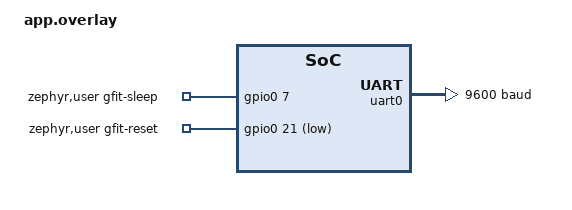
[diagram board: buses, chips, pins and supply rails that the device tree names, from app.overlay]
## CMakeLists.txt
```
# SPDX-License-Identifier: Apache-2.0

cmake_minimum_required(VERSION 3.20.0)
find_package(Zephyr REQUIRED HINTS $ENV{ZEPHYR_BASE})
project(d52q_gfit_bridge)

target_sources(app PRIVATE
	src/main.c
	src/ble_ftms.c
	src/gfit_protocol.c
)
```

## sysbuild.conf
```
# Build MCUboot together with the application for the initial programmer flash.
SB_CONFIG_BOOTLOADER_MCUBOOT=y
```

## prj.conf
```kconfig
CONFIG_GPIO=y
CONFIG_SERIAL=y
CONFIG_UART_INTERRUPT_DRIVEN=y
CONFIG_CONSOLE=n
CONFIG_UART_CONSOLE=n

CONFIG_BT=y
CONFIG_BT_PERIPHERAL=y
CONFIG_BT_DEVICE_NAME="N-Bike"
CONFIG_BT_DEVICE_NAME_DYNAMIC=y
CONFIG_BT_DEVICE_APPEARANCE=1152

# OTA path for nRF Connect / Device Manager. Final partition sizing must be
# verified on the exact D52Q board and flash layout.
CONFIG_BOOTLOADER_MCUBOOT=y
CONFIG_MCUBOOT_SIGNATURE_KEY_FILE="C:/ncs/v3.3.1/bootloader/mcuboot/root-rsa-2048.pem"
CONFIG_FLASH=y
CONFIG_FLASH_MAP=y
CONFIG_STREAM_FLASH=y
CONFIG_ZCBOR=y
CONFIG_CRC=y
CONFIG_IMG_MANAGER=y
CONFIG_MCUMGR=y
CONFIG_MCUMGR_GRP_IMG=y
CONFIG_MCUMGR_GRP_OS=y
CONFIG_MCUMGR_TRANSPORT_BT=y
CONFIG_BT_L2CAP_TX_MTU=252
CONFIG_BT_BUF_ACL_RX_SIZE=256
CONFIG_BT_BUF_ACL_TX_SIZE=256
CONFIG_SYSTEM_WORKQUEUE_STACK_SIZE=2304
CONFIG_MAIN_STACK_SIZE=2176
```

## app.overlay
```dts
&pinctrl {
	uart0_default: uart0_default {
		group1 {
			psels = <NRF_PSEL(UART_TX, 0, 17)>,
				<NRF_PSEL(UART_RX, 0, 16)>;
		};
	};

	uart0_sleep: uart0_sleep {
		group1 {
			psels = <NRF_PSEL(UART_RX, 0, 16)>;
			low-power-enable;
		};

		group2 {
			psels = <NRF_PSEL(UART_TX, 0, 17)>;
			low-power-enable;
			bias-pull-up;
		};
	};
};

&uart0 {
	status = "okay";
	current-speed = <9600>;
	/delete-property/ hw-flow-control;
};

/ {
	zephyr,user {
		gfit-sleep-gpios = <&gpio0 7 GPIO_ACTIVE_HIGH>;
		gfit-reset-gpios = <&gpio0 21 GPIO_ACTIVE_LOW>;
	};
};
```

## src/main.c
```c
#include <stddef.h>
#include <stdint.h>
#include <string.h>
#include <zephyr/drivers/gpio.h>
#include <zephyr/drivers/uart.h>
#include <zephyr/kernel.h>

#include "ble_ftms.h"
#include "gfit_protocol.h"

#define UART_DEVICE_NODE DT_NODELABEL(uart0)
#define USER_NODE DT_PATH(zephyr_user)
#define UART_RX_RING_SIZE 256
#define GFIT_POLL_MS 5

#define GFIT_BOOT 0x6f
#define GFIT_EVENT 0xe0
#define GFIT_CUSTOM_EVENT 0xb1
#define GFIT_HR_EVENT 0xb2
#define GFIT_CONTROL_EVENT 0xb5
#define GFIT_PERIPHERAL_EVENT 0xba
#define GFIT_METRIC_PACKET 0xe1
#define GFIT_COMMAND 0xe2
#define GFIT_CUSTOM_PROTOCOL 0xfe

#define GFIT_CMD_SET_EQUIPMENT 0xe0
#define GFIT_CMD_SET_METRICS 0xe1
#define GFIT_CMD_SET_CHANNEL_CONFIGURATION 0xd1
#define GFIT_CMD_TRANSITION 0xd0
#define GFIT_CMD_SET_DEVICE_INFO 0xe4
#define GFIT_CMD_SET_HRP_PAIRING 0xe5
#define GFIT_CMD_GET_VERSION 0xd7
#define GFIT_CMD_HRP_DISCONNECT 0xd9

#define GFIT_DEVICE_INFO_HARDWARE 0x02
#define GFIT_DEVICE_INFO_FIRMWARE 0x04
#define GFIT_DEVICE_INFO_PRODUCT 0x05
#define GFIT_DEVICE_INFO_MANUFACTURER 0x06

#define GFIT_TAG_SPEED 0x21
#define GFIT_TAG_CADENCE 0x22
#define GFIT_TAG_POWER 0x2a
#define GFIT_TAG_RESISTANCE 0x33

#define GFIT_TRANSITION_READY 0x04

struct ring_buffer {
	uint16_t start;
	uint16_t end;
	uint8_t data[UART_RX_RING_SIZE];
};

struct bike_metrics {
	uint16_t speed_centi_kmh;
	uint16_t cadence_half_rpm;
	int16_t resistance_percent;
	int16_t power_watt;
};

struct gfit_config {
	uint8_t equipment_type;
	uint8_t equipment_flags[2];
	uint8_t channel_selector;
	uint8_t channel_mask;
	uint8_t state;
	uint8_t metric_template[GFIT_PAYLOAD_MAX];
	uint8_t metric_template_length;
	char product_name[21];
	char manufacturer_name[21];
	char firmware_revision[8];
	char hardware_revision[8];
};

static const struct device *const uart_dev = DEVICE_DT_GET(UART_DEVICE_NODE);
static const struct gpio_dt_spec gfit_sleep =
	GPIO_DT_SPEC_GET(USER_NODE, gfit_sleep_gpios);
static const struct gpio_dt_spec gfit_reset =
	GPIO_DT_SPEC_GET(USER_NODE, gfit_reset_gpios);
static struct ring_buffer uart_rx;
static struct gfit_parser parser;
static struct bike_metrics last_metrics;
static struct gfit_config gfit_config = {
	.product_name = "N-Bike",
	.manufacturer_name = "Waterrower GmbH",
};
static bool bridge_ready;
static bool gfit_control_active;

static bool ring_is_empty(const struct ring_buffer *ring)
{
	return ring->start == ring->end;
}

static bool ring_is_full(const struct ring_buffer *ring)
{
	return ((ring->end + 1U) % UART_RX_RING_SIZE) == ring->start;
}

static void ring_write(struct ring_buffer *ring, uint8_t byte)
{
	if (ring_is_full(ring)) {
		ring->start = (ring->start + 1U) % UART_RX_RING_SIZE;
	}
	ring->data[ring->end] = byte;
	ring->end = (ring->end + 1U) % UART_RX_RING_SIZE;
}

static uint8_t ring_read(struct ring_buffer *ring)
{
	uint8_t byte = 0;

	if (!ring_is_empty(ring)) {
		byte = ring->data[ring->start];
		ring->start = (ring->start + 1U) % UART_RX_RING_SIZE;
	}

	return byte;
}

static void uart_send(const uint8_t *data, size_t length)
{
	for (size_t i = 0; i < length; i++) {
		uart_poll_out(uart_dev, data[i]);
	}
}

static void gfit_send_payload(const uint8_t *payload, size_t length)
{
	uint8_t frame[GFIT_PAYLOAD_MAX + 3U];
	size_t frame_length;

	if (length > GFIT_PAYLOAD_MAX) {
		return;
	}

	gfit_make_frame(payload, length, frame, &frame_length);
	uart_send(frame, frame_length);
}

static void gfit_send_boot_event(void)
{
	const uint8_t payload[] = { GFIT_BOOT };

	gfit_send_payload(payload, sizeof(payload));
}

static void gfit_send_response(bool success)
{
	const uint8_t payload[] = {
		GFIT_COMMAND, 0xb0, GFIT_CUSTOM_PROTOCOL,
		0x01, success ? 0x01 : 0x00, 0x01, 0x00, 0x00,
	};

	gfit_send_payload(payload, sizeof(payload));
}

static void gfit_send_calibrated_status(bool calibrated)
{
	const uint8_t payload[] = {
		0x02, 0x01, calibrated ? 0x01 : 0x02, 0x00, 0x00,
	};

	gfit_send_payload(payload, sizeof(payload));
}

static void gfit_send_peripheral_event(bool connected)
{
	const uint8_t payload[] = {
		GFIT_EVENT, GFIT_PERIPHERAL_EVENT, connected ? 0x00 : 0x01,
	};

	gfit_send_payload(payload, sizeof(payload));
}

static void copy_ascii_field(char *target, size_t target_size,
			     const uint8_t *source, size_t source_length)
{
	size_t length = MIN(source_length, target_size - 1U);

	memcpy(target, source, length);
	target[length] = '\0';
}

static void copy_hex_revision(char *target, size_t target_size,
			      const uint8_t *source, size_t source_length)
{
	size_t pos = 0;

	for (size_t i = 0; i < source_length && pos + 2U < target_size; i++) {
		static const char hex[] = "0123456789ABCDEF";

		target[pos++] = hex[(source[i] >> 4) & 0x0f];
		target[pos++] = hex[source[i] & 0x0f];
	}
	target[pos] = '\0';
}

static uint16_t get_le16(const uint8_t *data)
{
	return (uint16_t)data[0] | ((uint16_t)data[1] << 8);
}

static void handle_metric_packet(const uint8_t *payload, size_t length)
{
	size_t pos = 2;

	while (pos < length) {
		uint8_t tag = payload[pos++];

		switch (tag) {
		case GFIT_TAG_CADENCE:
			if (pos + 2U <= length) {
				last_metrics.cadence_half_rpm = get_le16(&payload[pos]);
				pos += 2U;
			}
			break;
		case GFIT_TAG_RESISTANCE:
			if (pos + 2U <= length) {
				uint16_t raw = get_le16(&payload[pos]);

				last_metrics.resistance_percent = (int16_t)(raw / 2U);
				pos += 2U;
			}
			break;
		case GFIT_TAG_POWER:
			if (pos + 2U <= length) {
				last_metrics.power_watt = (int16_t)get_le16(&payload[pos]);
				pos += 2U;
			}
			break;
		case GFIT_TAG_SPEED:
			if (pos + 2U <= length) {
				uint16_t mm_per_sec = get_le16(&payload[pos]);
				uint32_t centi_kmh = ((uint32_t)mm_per_sec * 36U) / 100U;

				last_metrics.speed_centi_kmh = (uint16_t)centi_kmh;
				pos += 2U;
			}
			break;
		default:
			pos = length;
			break;
		}
	}

	(void)ble_ftms_notify_indoor_bike(last_metrics.speed_centi_kmh,
					  last_metrics.cadence_half_rpm,
					  last_metrics.resistance_percent,
					  last_metrics.power_watt);
}

static void handle_custom_protocol(const uint8_t *payload, size_t length)
{
	uint8_t operation;
	uint8_t target;

	if (length < 5U) {
		gfit_send_response(false);
		return;
	}

	operation = payload[3];
	target = payload[4];

	if (operation == 0x02U && (target == 0x01U || target == 0x02U)) {
		gfit_send_response(true);
		return;
	}

	if (operation == 0x04U) {
		gfit_send_response(true);
		gfit_send_calibrated_status(true);
		return;
	}

	gfit_send_response(false);
}

static void handle_device_info_command(const uint8_t *payload, size_t length)
{
	uint8_t info_type;
	const uint8_t *data;
	size_t data_length;

	if (length < 4U) {
		gfit_send_response(false);
		return;
	}

	info_type = payload[2];
	data = &payload[3];
	data_length = length - 3U;

	switch (info_type) {
	case GFIT_DEVICE_INFO_PRODUCT:
		copy_ascii_field(gfit_config.product_name,
				 sizeof(gfit_config.product_name),
				 data, data_length);
		(void)ble_ftms_set_name(gfit_config.product_name);
		break;
	case GFIT_DEVICE_INFO_MANUFACTURER:
		copy_ascii_field(gfit_config.manufacturer_name,
				 sizeof(gfit_config.manufacturer_name),
				 data, data_length);
		break;
	case GFIT_DEVICE_INFO_FIRMWARE:
		copy_hex_revision(gfit_config.firmware_revision,
				  sizeof(gfit_config.firmware_revision),
				  data, data_length);
		break;
	case GFIT_DEVICE_INFO_HARDWARE:
		copy_hex_revision(gfit_config.hardware_revision,
				  sizeof(gfit_config.hardware_revision),
				  data, data_length);
		break;
	default:
		break;
	}

	gfit_send_response(true);
}

static void handle_init_command(const uint8_t *payload, size_t length)
{
	uint8_t command = payload[1];

	switch (command) {
	case GFIT_CMD_SET_EQUIPMENT:
		if (length >= 5U) {
			gfit_config.equipment_type = payload[2];
			gfit_config.equipment_flags[0] = payload[3];
			gfit_config.equipment_flags[1] = payload[4];
		}
		gfit_send_response(length >= 3U);
		break;
	case GFIT_CMD_SET_METRICS:
		gfit_config.metric_template_length =
			(uint8_t)MIN(length, sizeof(gfit_config.metric_template));
		memcpy(gfit_config.metric_template, payload,
		       gfit_config.metric_template_length);
		gfit_send_response(true);
		break;
	case GFIT_CMD_SET_CHANNEL_CONFIGURATION:
		if (length >= 4U) {
			gfit_config.channel_selector = payload[2];
			gfit_config.channel_mask = payload[3];
		}
		gfit_send_response(length >= 4U);
		break;
	case GFIT_CMD_SET_DEVICE_INFO:
		handle_device_info_command(payload, length);
		break;
	case GFIT_CMD_SET_HRP_PAIRING:
	case GFIT_CMD_GET_VERSION:
	case GFIT_CMD_HRP_DISCONNECT:
		gfit_send_response(true);
		break;
	case GFIT_CMD_TRANSITION:
		if (length >= 3U) {
			gfit_config.state = payload[2];
			if (gfit_config.state == GFIT_TRANSITION_READY) {
				bridge_ready = true;
				(void)ble_ftms_set_enabled(true);
			}
		}
		gfit_send_response(length >= 3U);
		break;
	default:
		gfit_send_response(true);
		break;
	}
}

static void handle_gfit_command(const uint8_t *payload, size_t length)
{
	if (length >= 2U && payload[1] == GFIT_METRIC_PACKET) {
		handle_metric_packet(payload, length);
		return;
	}

	if (length >= 3U && payload[1] == GFIT_CUSTOM_EVENT &&
	    payload[2] == GFIT_CUSTOM_PROTOCOL) {
		handle_custom_protocol(payload, length);
		return;
	}

	if (length >= 2U) {
		handle_init_command(payload, length);
	}
}

static void handle_gfit_payload(const uint8_t *payload, size_t length)
{
	if (!gfit_control_active) {
		return;
	}

	if (length == 0U) {
		return;
	}

	if (payload[0] == GFIT_COMMAND) {
		handle_gfit_command(payload, length);
	}
}

static void uart_irq_handler(const struct device *dev, void *user_data)
{
	ARG_UNUSED(user_data);

	if (!uart_irq_update(dev)) {
		return;
	}

	while (uart_irq_rx_ready(dev)) {
		uint8_t data[16];
		int read = uart_fifo_read(dev, data, sizeof(data));

		if (read <= 0) {
			break;
		}

		for (int i = 0; i < read; i++) {
			ring_write(&uart_rx, data[i]);
		}
	}
}

static void ble_connection_changed(bool connected)
{
	if (!gfit_control_active) {
		return;
	}

	gfit_send_peripheral_event(connected);
}

static bool gfit_control_pins_active(void)
{
	bool awake = true;
	bool reset_released = true;

	if (gpio_is_ready_dt(&gfit_sleep)) {
		awake = gpio_pin_get_dt(&gfit_sleep) == 0;
	}

	if (gpio_is_ready_dt(&gfit_reset)) {
		reset_released = gpio_pin_get_dt(&gfit_reset) > 0;
	}

	return awake && reset_released;
}

static void update_gfit_control_state(void)
{
	bool active = gfit_control_pins_active();

	if (active == gfit_control_active) {
		return;
	}

	gfit_control_active = active;
	if (active) {
		gfit_parser_init(&parser);
		bridge_ready = true;
		(void)ble_ftms_set_enabled(true);
		gfit_send_boot_event();
	} else {
		bridge_ready = false;
		(void)ble_ftms_set_enabled(false);
		gfit_parser_init(&parser);
		uart_rx.start = uart_rx.end;
	}
}

static void init_gfit_control_pins(void)
{
	if (gpio_is_ready_dt(&gfit_sleep)) {
		(void)gpio_pin_configure_dt(&gfit_sleep, GPIO_INPUT);
	}

	if (gpio_is_ready_dt(&gfit_reset)) {
		(void)gpio_pin_configure_dt(&gfit_reset, GPIO_INPUT);
	}
}

static void process_uart(void)
{
	while (!ring_is_empty(&uart_rx)) {
		const uint8_t *payload;
		size_t length;
		uint8_t byte = ring_read(&uart_rx);

		if (gfit_parser_push(&parser, byte, &payload, &length)) {
			handle_gfit_payload(payload, length);
		}
	}
}

int main(void)
{
	int ret;

	if (!device_is_ready(uart_dev)) {
		return 0;
	}

	gfit_parser_init(&parser);
	init_gfit_control_pins();

	ret = uart_irq_callback_user_data_set(uart_dev, uart_irq_handler, NULL);
	if (ret < 0) {
		return 0;
	}
	uart_irq_rx_enable(uart_dev);

	(void)ble_ftms_init(ble_connection_changed);
	update_gfit_control_state();

	while (1) {
		update_gfit_control_state();
		process_uart();
		ARG_UNUSED(bridge_ready);
		k_msleep(GFIT_POLL_MS);
	}

	return 0;
}
```

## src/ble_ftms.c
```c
#include "ble_ftms.h"

#include <errno.h>
#include <stddef.h>
#include <string.h>
#include <zephyr/bluetooth/bluetooth.h>
#include <zephyr/bluetooth/conn.h>
#include <zephyr/bluetooth/gatt.h>
#include <zephyr/sys/byteorder.h>

#define BT_UUID_FTMS_VAL 0x1826
#define BT_UUID_FTMS_FEATURE_VAL 0x2acc
#define BT_UUID_INDOOR_BIKE_DATA_VAL 0x2ad2
#define DEVICE_NAME_MAX 20

static struct bt_conn *current_conn;
static bool bt_ready;
static bool ftms_enabled;
static bool ftms_advertising;
static bool indoor_bike_notify_enabled;
static ble_ftms_conn_cb_t connection_cb;
static char device_name[DEVICE_NAME_MAX + 1U] = CONFIG_BT_DEVICE_NAME;

static const struct bt_uuid_16 ftms_uuid = BT_UUID_INIT_16(BT_UUID_FTMS_VAL);
static const struct bt_uuid_16 ftms_feature_uuid =
	BT_UUID_INIT_16(BT_UUID_FTMS_FEATURE_VAL);
static const struct bt_uuid_16 indoor_bike_data_uuid =
	BT_UUID_INIT_16(BT_UUID_INDOOR_BIKE_DATA_VAL);

static const uint8_t ftms_feature[8] = {
	0x00, 0x00, 0x00, 0x00,
	0x00, 0x00, 0x00, 0x00,
};

static const struct bt_data advertising_data[] = {
	BT_DATA_BYTES(BT_DATA_FLAGS, (BT_LE_AD_GENERAL | BT_LE_AD_NO_BREDR)),
	BT_DATA_BYTES(BT_DATA_UUID16_ALL, BT_UUID_16_ENCODE(BT_UUID_FTMS_VAL)),
};

static ssize_t read_ftms_feature(struct bt_conn *conn,
				 const struct bt_gatt_attr *attr,
				 void *buf, uint16_t len, uint16_t offset)
{
	return bt_gatt_attr_read(conn, attr, buf, len, offset,
				 ftms_feature, sizeof(ftms_feature));
}

static void indoor_bike_ccc_changed(const struct bt_gatt_attr *attr,
				    uint16_t value)
{
	ARG_UNUSED(attr);
	indoor_bike_notify_enabled = (value == BT_GATT_CCC_NOTIFY);
}

BT_GATT_SERVICE_DEFINE(ftms_service,
	BT_GATT_PRIMARY_SERVICE(&ftms_uuid.uuid),
	BT_GATT_CHARACTERISTIC(&ftms_feature_uuid.uuid,
			       BT_GATT_CHRC_READ,
			       BT_GATT_PERM_READ,
			       read_ftms_feature, NULL, NULL),
	BT_GATT_CHARACTERISTIC(&indoor_bike_data_uuid.uuid,
			       BT_GATT_CHRC_NOTIFY,
			       BT_GATT_PERM_NONE,
			       NULL, NULL, NULL),
	BT_GATT_CCC(indoor_bike_ccc_changed,
		    BT_GATT_PERM_READ | BT_GATT_PERM_WRITE),
);

static int start_advertising(void)
{
	const struct bt_data scan_response_data[] = {
		{
			.type = BT_DATA_NAME_COMPLETE,
			.data_len = (uint8_t)strlen(device_name),
			.data = (const uint8_t *)device_name,
		},
	};
	int err;

	if (!bt_ready || ftms_advertising || current_conn != NULL) {
		return 0;
	}

	err = bt_le_adv_start(BT_LE_ADV_CONN_FAST_2,
			      advertising_data, ARRAY_SIZE(advertising_data),
			      scan_response_data, ARRAY_SIZE(scan_response_data));
	if (err == -EALREADY) {
		err = 0;
	}

	if (err == 0) {
		ftms_advertising = true;
	}

	return err;
}

static int stop_advertising(void)
{
	int err;

	if (!ftms_advertising) {
		return 0;
	}

	err = bt_le_adv_stop();
	if (err == -EALREADY || err == -EINVAL || err == -EACCES) {
		err = 0;
	}

	if (err == 0) {
		ftms_advertising = false;
	}

	return err;
}

static void connected(struct bt_conn *conn, uint8_t err)
{
	struct bt_conn_info info;

	if (bt_conn_get_info(conn, &info) != 0 ||
	    info.role != BT_CONN_ROLE_PERIPHERAL) {
		return;
	}

	if (err != 0) {
		if (ftms_enabled) {
			(void)start_advertising();
		}
		return;
	}

	current_conn = bt_conn_ref(conn);
	ftms_advertising = false;
	if (connection_cb != NULL) {
		connection_cb(true);
	}
}

static void disconnected(struct bt_conn *conn, uint8_t reason)
{
	ARG_UNUSED(reason);

	if (current_conn != conn) {
		return;
	}

	bt_conn_unref(current_conn);
	current_conn = NULL;
	indoor_bike_notify_enabled = false;
	if (connection_cb != NULL) {
		connection_cb(false);
	}

	if (ftms_enabled) {
		(void)start_advertising();
	}
}

BT_CONN_CB_DEFINE(conn_callbacks) = {
	.connected = connected,
	.disconnected = disconnected,
};

int ble_ftms_init(ble_ftms_conn_cb_t cb)
{
	int err;

	connection_cb = cb;
	if (bt_ready) {
		return 0;
	}

	err = bt_enable(NULL);
	if (err == 0) {
		bt_ready = true;
	}

	return err;
}

int ble_ftms_set_enabled(bool enabled)
{
	int err;

	if (!bt_ready) {
		err = ble_ftms_init(connection_cb);
		if (err != 0) {
			return err;
		}
	}

	if (enabled) {
		err = start_advertising();
		if (err == 0) {
			ftms_enabled = true;
		}
		return err;
	}

	ftms_enabled = false;
	err = stop_advertising();
	if (current_conn != NULL) {
		int disconnect_err = bt_conn_disconnect(current_conn,
							BT_HCI_ERR_REMOTE_USER_TERM_CONN);
		if (err == 0) {
			err = disconnect_err;
		}
	}

	return err;
}

bool ble_ftms_is_enabled(void)
{
	return ftms_enabled;
}

int ble_ftms_set_name(const char *name)
{
	size_t length;
	bool restart_adv = ftms_advertising;
	int err = 0;

	if (name == NULL || name[0] == '\0') {
		return -EINVAL;
	}

	length = MIN(strlen(name), DEVICE_NAME_MAX);
	memcpy(device_name, name, length);
	device_name[length] = '\0';

	if (bt_ready) {
		err = bt_set_name(device_name);
	}

	if (restart_adv) {
		(void)stop_advertising();
		err = start_advertising();
	}

	return err;
}

bool ble_ftms_is_connected(void)
{
	return current_conn != NULL;
}

int ble_ftms_notify_indoor_bike(uint16_t speed_centi_kmh,
				uint16_t cadence_half_rpm,
				int16_t resistance_percent,
				int16_t power_watt)
{
	uint8_t data[10];

	if (current_conn == NULL || !indoor_bike_notify_enabled) {
		return 0;
	}

	sys_put_le16(0x0064, &data[0]);
	sys_put_le16(speed_centi_kmh, &data[2]);
	sys_put_le16(cadence_half_rpm, &data[4]);
	sys_put_le16((uint16_t)resistance_percent, &data[6]);
	sys_put_le16((uint16_t)power_watt, &data[8]);

	return bt_gatt_notify(current_conn, &ftms_service.attrs[4],
			      data, sizeof(data));
}
```

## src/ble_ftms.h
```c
#ifndef BLE_FTMS_H
#define BLE_FTMS_H

#include <stdbool.h>
#include <stdint.h>

typedef void (*ble_ftms_conn_cb_t)(bool connected);

int ble_ftms_init(ble_ftms_conn_cb_t cb);
int ble_ftms_set_enabled(bool enabled);
int ble_ftms_set_name(const char *name);
bool ble_ftms_is_enabled(void);
bool ble_ftms_is_connected(void);
int ble_ftms_notify_indoor_bike(uint16_t speed_centi_kmh,
				uint16_t cadence_half_rpm,
				int16_t resistance_percent,
				int16_t power_watt);

#endif
```

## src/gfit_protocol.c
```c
#include "gfit_protocol.h"

#include <stdbool.h>

void gfit_parser_init(struct gfit_parser *parser)
{
	parser->state = GFIT_WAIT_START;
	parser->length = 0;
	parser->index = 0;
	parser->checksum = 0;
}

uint8_t gfit_checksum(const uint8_t *payload, size_t length)
{
	uint8_t checksum = GFIT_FRAME_START ^ (uint8_t)length;

	for (size_t i = 0; i < length; i++) {
		checksum ^= payload[i];
	}

	return checksum;
}

bool gfit_parser_push(struct gfit_parser *parser, uint8_t byte,
		      const uint8_t **payload, size_t *length)
{
	switch (parser->state) {
	case GFIT_WAIT_START:
		if (byte == GFIT_FRAME_START) {
			parser->state = GFIT_WAIT_LENGTH;
			parser->checksum = GFIT_FRAME_START;
		}
		break;
	case GFIT_WAIT_LENGTH:
		if (byte > GFIT_PAYLOAD_MAX) {
			gfit_parser_init(parser);
			break;
		}
		parser->length = byte;
		parser->index = 0;
		parser->checksum ^= byte;
		parser->state = byte == 0U ? GFIT_WAIT_CHECKSUM : GFIT_COLLECT_PAYLOAD;
		break;
	case GFIT_COLLECT_PAYLOAD:
		parser->payload[parser->index++] = byte;
		parser->checksum ^= byte;
		if (parser->index == parser->length) {
			parser->state = GFIT_WAIT_CHECKSUM;
		}
		break;
	case GFIT_WAIT_CHECKSUM:
		if (byte == parser->checksum) {
			*payload = parser->payload;
			*length = parser->length;
			gfit_parser_init(parser);
			return true;
		}
		gfit_parser_init(parser);
		break;
	}

	return false;
}

void gfit_make_frame(const uint8_t *payload, size_t length,
		     uint8_t *frame, size_t *frame_length)
{
	size_t pos = 0;

	frame[pos++] = GFIT_FRAME_START;
	frame[pos++] = (uint8_t)length;
	for (size_t i = 0; i < length; i++) {
		frame[pos++] = payload[i];
	}
	frame[pos++] = gfit_checksum(payload, length);
	*frame_length = pos;
}
```

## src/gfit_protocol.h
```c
#ifndef GFIT_PROTOCOL_H
#define GFIT_PROTOCOL_H

#include <stdbool.h>
#include <stddef.h>
#include <stdint.h>

#define GFIT_FRAME_START 0xa4
#define GFIT_PAYLOAD_MAX 40

struct gfit_parser {
	enum {
		GFIT_WAIT_START,
		GFIT_WAIT_LENGTH,
		GFIT_COLLECT_PAYLOAD,
		GFIT_WAIT_CHECKSUM,
	} state;
	uint8_t payload[GFIT_PAYLOAD_MAX];
	uint8_t length;
	uint8_t index;
	uint8_t checksum;
};

void gfit_parser_init(struct gfit_parser *parser);
bool gfit_parser_push(struct gfit_parser *parser, uint8_t byte,
		      const uint8_t **payload, size_t *length);
uint8_t gfit_checksum(const uint8_t *payload, size_t length);
void gfit_make_frame(const uint8_t *payload, size_t length,
		     uint8_t *frame, size_t *frame_length);

#endif
```
